# GPTIMER10 register map
Vendor: Texas Instruments
Peripheral module from a debugger description file (folder omap34xx).
Registers are 32-bit, read-write, reset 0x0 unless marked. A register's access mark holds for its fields unless they carry their own. Offsets are as the file gives them; lines under a group give offsets from that group; [hi:lo] are bit positions; {n}, {i} and the like mark numbered series; 'fields as' and 'values as' point back to an identical list; <NAME> marks a mode.

## GPTIMER10
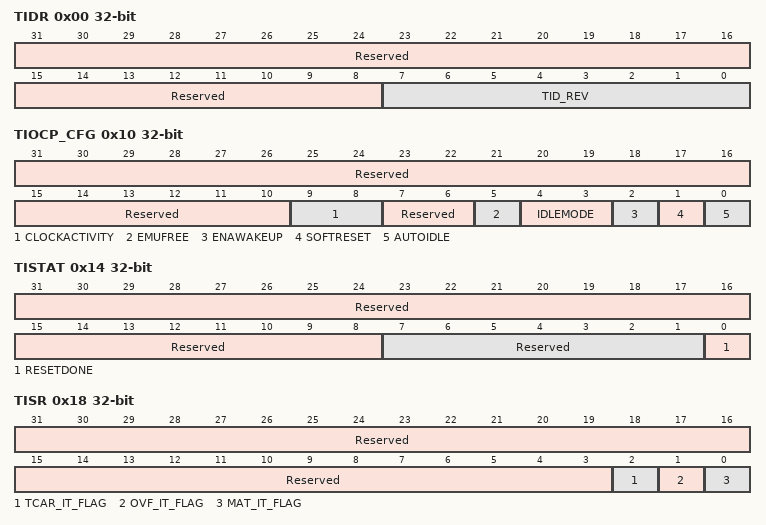
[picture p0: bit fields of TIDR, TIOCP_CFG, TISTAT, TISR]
0x00 TIDR ro (reset mask 0xFFFFFF00) — This register contains the IP revision code.
  [31:8] Reserved — Reads return 0.
  [7:0] TID_REV — IP revision[7:4] . Major revision . [3:0] . Minor revision . Examples: 0x10 for 1.0, 0x21 for 2.1 .
0x10 TIOCP_CFG access not given — This register controls the various parameters of the GP timer L4 interface.
  [31:10] Reserved ro — Write 0s for future compatibility. Reads return 0.
  [9:8] CLOCKACTIVITY rw — Clock activity during wakeup mode period:
    0=L4 interface and Functional clocks can be switched off; 1=L4 interface clock is maintained during wake-up period; Functional clock can be switched off; 2=L4 interface clock can be switched off; Functional clock is maintained during wake-up period; 3=L4 interface and Functional clocks are maintained during wake-up period
  [7:6] Reserved ro — Write 0s for future compatibility. Reads return 0.
  [5] EMUFREE rw — Emulation mode
    0=Timer counter frozen in emulation; 1=Timer counter free-running in emulation
  [4:3] IDLEMODE rw — Power management, req/ack control
    0=Force-idle. An idle request is acknowledged unconditionally.; 1=No-idle. An idle request is never acknowledged.; 2=Smart-idle. Acknowledgement to an idle request is given based on the internal activity of the module.; 3=Reserved. Do not use.
  [2] ENAWAKEUP rw — Wake-up feature global control
    0=No wake-up line assertion in idle mode; 1=Wake-up line assertion enabled in smart-idle mode
  [1] SOFTRESET rw — Software reset. This bit is automatically reset by the hardware. During reads, it always returns 0.
    0=Normal mode; 1=The module is reset
  [0] AUTOIDLE — Internal L4 interface clock gating strategy
    0=L4 interface clock is free-running; 1=Automatic L4 interface clock gating strategy is applied, based on the L4 interface activity
0x14 TISTAT ro — This register provides status information about the module, excluding the interrupt status information.
  [31:8] Reserved — Reads return 0.
  [7:1] Reserved — Reads return 0.
  [0] RESETDONE — Internal reset monitoring
    0=Internal module reset is ongoing; 1=Reset completed
0x18 TISR access per field — This register shows which interrupt events are pending inside the module.
  [31:3] Reserved ro — Reads return 0.
  [2] TCAR_IT_FLAG rw — Pending capture interrupt status
    0=TCAR_IT_FLAG_0_r (No capture interrupt event pending); 0=TCAR_IT_FLAG_0_w (Status unchanged); 1=TCAR_IT_FLAG_1_r (Capture interrupt event pending); 1=TCAR_IT_FLAG_1_w (Status bit cleared)
  [1] OVF_IT_FLAG rw — Pending overflow interrupt status
    0=OVF_IT_FLAG_0_r (No overflow interrupt pending); 0=OVF_IT_FLAG_0_w (Status unchanged); 1=OVF_IT_FLAG_1_r (Overflow interrupt pending); 1=OVF_IT_FLAG_1_w (Status bit cleared)
  [0] MAT_IT_FLAG rw — Pending match interrupt status
    0=MAT_IT_FLAG_0_r (No match interrupt pending); 0=MAT_IT_FLAG_0_w (Status unchanged); 1=MAT_IT_FLAG_1_r (Match interrupt pending); 1=MAT_IT_FLAG_1_w (Status bit cleared)
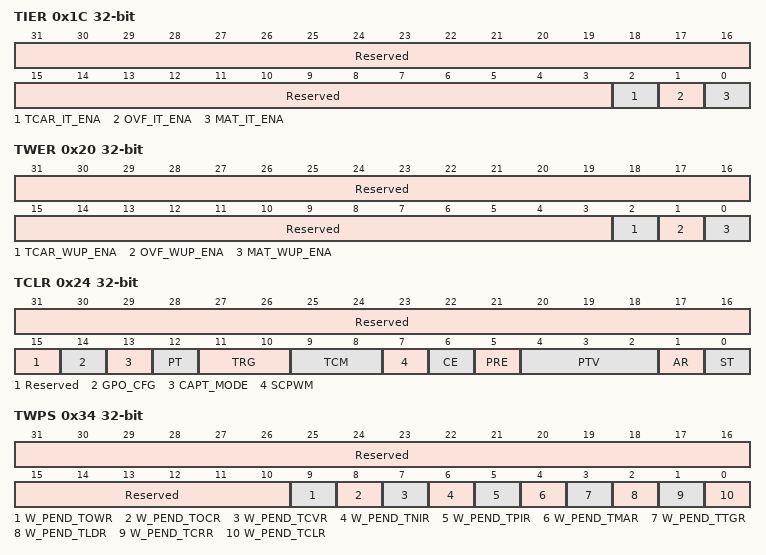
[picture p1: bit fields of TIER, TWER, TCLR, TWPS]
0x1C TIER access per field — This register controls (enable/disable) the interrupt events.
  [31:3] Reserved ro — Reads return 0.
  [2] TCAR_IT_ENA rw — Enable capture interrupt
    0=Disable capture interrupt; 1=Enable capture interrupt
  [1] OVF_IT_ENA rw — Enable overflow interrupt
    0=Disable overflow interrupt; 1=Enable overflow interrupt
  [0] MAT_IT_ENA rw — Enable match interrupt
    0=Disable match interrupt; 1=Enable match interrupt
0x20 TWER access per field — This register controls (enable/disable) the wake-up feature on specific interrupt events.
  [31:3] Reserved ro — Reads return 0
  [2] TCAR_WUP_ENA rw — Enable capture wake-up
    0=Disable capture wake-up; 1=Enable capture wake-up
  [1] OVF_WUP_ENA rw — Enable overflow wake-up
    0=Disable overflow wake-up; 1=Enable overflow wake-up
  [0] MAT_WUP_ENA rw — Enable match wake-up
    0=Disable match wake-up; 1=Enable match wake-up
0x24 TCLR access not given (reset mask 0xFFFFFFE3) — This register controls optional features specific to the timer functionality.
  [31:15] Reserved ro — Reads return 0.
  [14] GPO_CFG rw — PWM output/event detection input pin direction control:
    0=Configures the pin as an output (needed when PWM mode is required); 1=Configures the pin as an input (needed when capture mode is required)
  [13] CAPT_MODE rw — Capture mode select bit (first/second)
    0=Capture the first enabled capture event in; 1=Capture the second enabled capture event in
  [12] PT rw — Pulse or toggle select bit
    0=Pulse modulation; 1=Toggle modulation
  [11:10] TRG rw — Trigger output mode
    0=No trigger; 1=Overflow trigger; 2=Overflow and match trigger
  [9:8] TCM rw — Transition capture mode
    0=No capture; 1=Capture on rising edges of EVENT_CAPTURE pin; 2=Capture on falling edges of EVENT_CAPTURE pin; 3=Capture on both edges of EVENT_CAPTURE pin
  [7] SCPWM rw — Pulse-width-modulation output pin default setting when counter is stopped or trigger output mode is set to no trigger.
    0=Default value of PWM_out output: 0; 1=Default value of PWM_out output: 1
  [6] CE rw — Compare enable
    0=Compare disabled; 1=Compare enabled
  [5] PRE rw — Prescaler enable
    0=Prescaler disabled; 1=Prescaler enabled
  [4:2] PTV — Trigger output mode
    0=The timer counter is prescaled with the value: 2(PTV+1). Example: PTV = 3, counter increases value (if started) after 16 functional clock periods. RW 0x0
  [1] AR rw — Autoreload mode
    0=One-shot mode overflow; 1=Autoreload mode overflow
  [0] ST rw — Start/stop timer control
    0=Stop the timer; 1=Start the timer
0x28 TCRR — This register holds the value of the internal counter.
  [31:0] TIMER_COUNTER — The value of the timer counter register
0x2C TLDR — This register holds the timer load values.
  [31:0] LOAD_VALUE — The value of the timer load register
0x30 TTGR reset 0xFFFFFFFF — This register triggers a counter reload of timer by writing any value in it.
  [31:0] TTGR_VALUE — The value of the trigger register. During reads, it always returns 0xFFFFFFFF.
0x34 TWPS ro — This register indicates if a Write-Posted is pending.
  [31:10] Reserved — Reads return 0.
  [9] W_PEND_TOWR — Write pending for register GPT_TOWRReserved for instances 3, 4, 5, 6, 7, 8, 9, 11, 12 Read returns reset value. R 0 .
    0=Overflow wrapping register write not pending; 1=Overflow wrapping register write pending
  [8] W_PEND_TOCR — Write pending for register GPT_TOCRReserved for instances 3, 4, 5, 6, 7, 8, 9, 11, 12 Read returns reset value. R 0 .
    0=Overflow counter register write not pending; 1=Overflow counter register write pending
  [7] W_PEND_TCVR — Write pending for register GPT_TCVRReserved for instances 3, 4, 5, 6, 7, 8, 9, 11, 12 Read returns reset value. R 0 .
    0=Counter value register write not pending; 1=Counter value register write pending
  [6] W_PEND_TNIR — Write pending for register GPT_TNIRReserved for instances 3, 4, 5, 6, 7, 8, 9, 11, 12 Read returns reset value. R 0 .
    0=Negative increment register write not pending; 1=Negative increment register write pending
  [5] W_PEND_TPIR — Write pending for register GPT_TPIRReserved for instances 3, 4, 5, 6, 7, 8, 9, 11, 12 Read returns reset value. R 0 .
    0=Positive increment register write not pending; 1=Positive increment register write pending
  [4] W_PEND_TMAR — Write pending for register GPT_TMAR
    0=Match register write not pending; 1=Match register write pending
  [3] W_PEND_TTGR — Write pending for register GPT_TTGR
    0=Trigger register write not pending; 1=Trigger register write pending
  [2] W_PEND_TLDR — Write pending for register GPT_TLDR
    0=Load register write not pending; 1=Load register write pending
  [1] W_PEND_TCRR — Write pending for register GPT_TCRR
    0=Counter register write not pending; 1=Counter register write pending
  [0] W_PEND_TCLR — Write pending for register GPT_TCLR
    0=Control register write not pending; 1=Control register write pending
0x38 TMAR — This register holds the value to be compared with the counter value.
  [31:0] COMPARE_VALUE — The value of the match register
0x3C TCAR1 ro — This register holds the first captured value of the counter register.
  [31:0] CAPTURE_VALUE1 — The value of first captured counter register
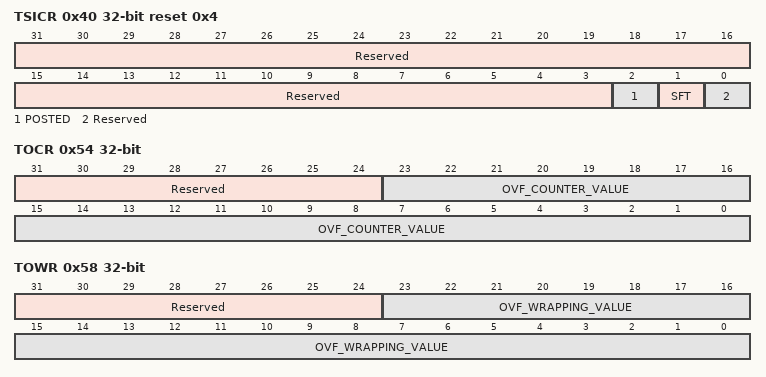
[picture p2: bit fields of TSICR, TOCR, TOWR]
0x40 TSICR access per field reset 0x4 — This register contains the bits that control the interface between the L4 interface and functional clock domains-posted mode and functional SW reset.
  [31:3] Reserved ro — Reads return 0.
  [2] POSTED rw — Posted mode selection
    0=Non-posted mode selected; 1=Posted mode selected
  [1] SFT rw — Reset software functional registers. This bit is automatically reset by the hardware. During reads, it always returns 0.
    0=Normal functional mode; 1=The functional registers are reset
  [0] Reserved ro — Reads return 0.
0x44 TCAR2 ro — This register holds the second captured value of the counter register.
  [31:0] CAPTURE_VALUE2 — The value of second captured counter register
0x48 TPIR — This register is used for 1 ms tick generation. The register holds the value of the positive increment. The value of this register is added with the value of the to define whether next value loaded in will be the sub-period value or the over-period value.
  [31:0] POSITIVE_INC_VALUE — The value of positive increment.
0x4C TNIR — This register is used for 1 ms tick generation. The register holds the value of the negative increment. The value of this register is added with the value of the to define whether next value loaded in will be the sub-period value or the over-period value.
  [31:0] NEGATIVE_INC_VALUE — The value of negative increment.
0x50 TCVR — This register is used for 1 ms tick generation. The register defines whether next value loaded in will be the sub-period value or the over-period value.
  [31:0] COUNTER_VALUE — The value of CVR counter.
0x54 TOCR — This register is used to mask the tick interrupt for a selected number of ticks.
  [31:24] Reserved — Reads return 0.
  [23:0] OVF_COUNTER_VALUE — The number of overflow events.
0x58 TOWR — This register holds the number of masked overflow interrupts.
  [31:24] Reserved — Reads return 0.
  [23:0] OVF_WRAPPING_VALUE — The number of masked interrupts.
